# EFM32JG12B500F1024GL125 register map
File version: 4.0.0
CPU: CM3 r2p1, little endian, MPU, no FPU, 3 interrupt priority bits
Registers are 32-bit, read-write, reset 0x0 unless marked. A register's access mark holds for its fields unless they carry their own. Offsets are from the block's base; [hi:lo] are bit positions; {n}, {i} and the like mark numbered series.

## VDAC0
Base 0x40008000
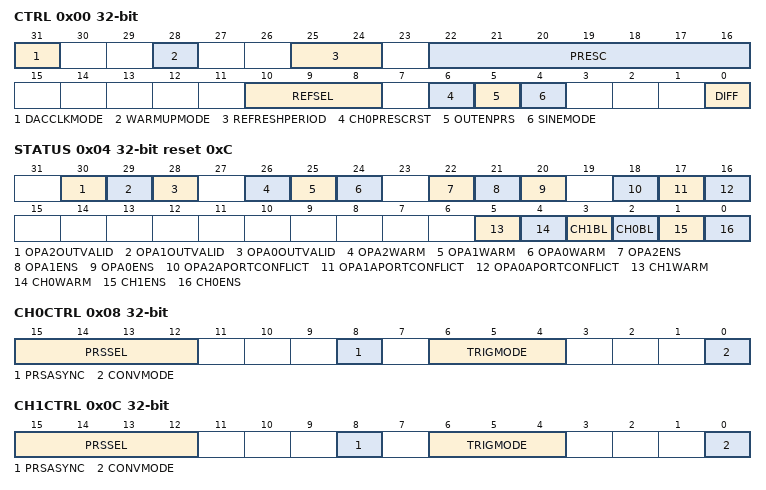
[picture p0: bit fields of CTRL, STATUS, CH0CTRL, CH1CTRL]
0x00 CTRL — Control Register
  [31] DACCLKMODE — Clock Mode
  [28] WARMUPMODE
  [25:24] REFRESHPERIOD
    0=8CYCLES (All channels with enabled refresh are refreshed every 8 DAC_CLK cycles); 1=16CYCLES (All channels with enabled refresh are refreshed every 16 DAC_CLK cycles); 2=32CYCLES (All channels with enabled refresh are refreshed every 32 DAC_CLK cycles); 3=64CYCLES (All channels with enabled refresh are refreshed every 64 DAC_CLK cycles)
  [22:16] PRESC — Prescaler Setting for DAC Clock
    0=NODIVISION
  [10:8] REFSEL — Reference Selection
    0=1V25LN (Internal low noise 1.25 V bandgap reference); 1=2V5LN (Internal low noise 2.5 V bandgap reference); 2=1V25 (Internal 1.25 V bandgap reference); 3=2V5 (Internal 2.5 V bandgap reference); 4=VDD (AVDD reference); 6=EXT (External pin reference)
  [6] CH0PRESCRST — Channel 0 Start Reset Prescaler
  [5] OUTENPRS — PRS Controlled Output Enable
  [4] SINEMODE
  [0] DIFF — Differential Mode
0x04 STATUS ro reset 0xC
  [30] OPA2OUTVALID — OPA2 Output Valid Status
  [29] OPA1OUTVALID — OPA1 Output Valid Status
  [28] OPA0OUTVALID — OPA0 Output Valid Status
  [26] OPA2WARM — OPA2 Warm Status
  [25] OPA1WARM — OPA1 Warm Status
  [24] OPA0WARM — OPA0 Warm Status
  [22] OPA2ENS — OPA2 Enabled Status
  [21] OPA1ENS — OPA1 Enabled Status
  [20] OPA0ENS — OPA0 Enabled Status
  [18] OPA2APORTCONFLICT — OPA2 Bus Conflict Output
  [17] OPA1APORTCONFLICT — OPA1 Bus Conflict Output
  [16] OPA0APORTCONFLICT — OPA0 Bus Conflict Output
  [5] CH1WARM — Channel 1 Warm
  [4] CH0WARM — Channel 0 Warm
  [3] CH1BL — Channel 1 Buffer Level
  [2] CH0BL — Channel 0 Buffer Level
  [1] CH1ENS — Channel 1 Enabled Status
  [0] CH0ENS — Channel 0 Enabled Status
0x08 CH0CTRL — Channel 0 Control Register
  [15:12] PRSSEL — Channel 0 PRS Trigger Select
    {v}=PRSCH{v} (PRS ch {v} triggers a conversion.) (v=0..11)
  [8] PRSASYNC — Channel 0 PRS Asynchronous Enable
  [6:4] TRIGMODE — Channel 0 Trigger Mode
    0=SW (Channel 0 is triggered by CH0DATA or COMBDATA write); 1=PRS (Channel 0 is triggered by PRS input); 2=REFRESH (Channel 0 is triggered by Refresh timer); 3=SWPRS (Channel 0 is triggered by CH0DATA/COMBDATA write or PRS input); 4=SWREFRESH (Channel 0 is triggered by CH0DATA/COMBDATA write or Refresh timer); 5=LESENSE (Channel 0 is triggered by LESENSE)
  [0] CONVMODE — Conversion Mode
0x0C CH1CTRL — Channel 1 Control Register
  [15:12] PRSSEL — Channel 1 PRS Trigger Select
    {v}=PRSCH{v} (PRS ch {v} triggers a conversion.) (v=0..11)
  [8] PRSASYNC — Channel 1 PRS Asynchronous Enable
  [6:4] TRIGMODE — Channel 1 Trigger Mode
    0=SW (Channel 1 is triggered by CH1DATA or COMBDATA write); 1=PRS (Channel 1 is triggered by PRS input); 2=REFRESH (Channel 1 is triggered by Refresh timer); 3=SWPRS (Channel 1 is triggered by CH1DATA/COMBDATA write or PRS input); 4=SWREFRESH (Channel 1 is triggered by CH1DATA/COMBDATA write or Refresh timer); 5=LESENSE (Channel 1 is triggered by LESENSE)
  [0] CONVMODE — Conversion Mode
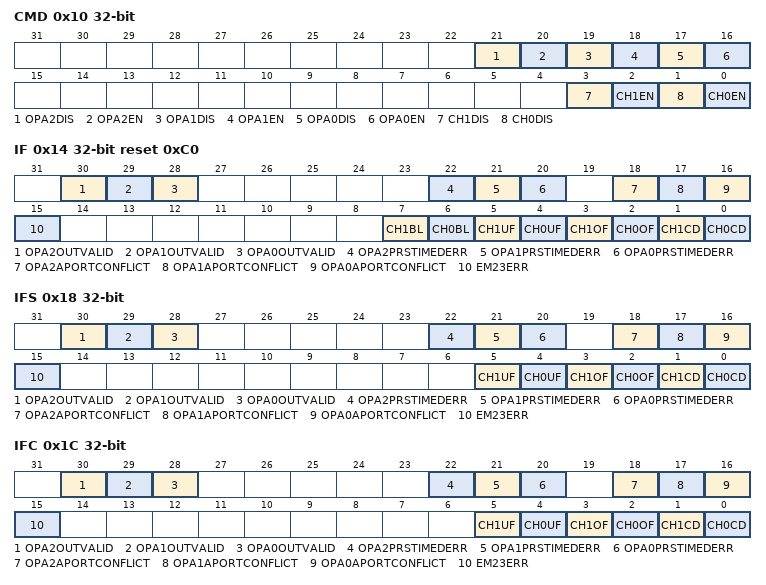
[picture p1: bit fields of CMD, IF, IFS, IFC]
0x10 CMD wo — Command Register
  [21] OPA2DIS — OPA2 Disable
  [20] OPA2EN — OPA2 Enable
  [19] OPA1DIS — OPA1 Disable
  [18] OPA1EN — OPA1 Enable
  [17] OPA0DIS — OPA0 Disable
  [16] OPA0EN — OPA0 Enable
  [3] CH1DIS — DAC Channel 1 Disable
  [2] CH1EN — DAC Channel 1 Enable
  [1] CH0DIS — DAC Channel 0 Disable
  [0] CH0EN — DAC Channel 0 Enable
0x14 IF ro reset 0xC0 — Interrupt Flag Register
  [30] OPA2OUTVALID — OPA3 Output Valid Interrupt Flag
  [29] OPA1OUTVALID — OPA1 Output Valid Interrupt Flag
  [28] OPA0OUTVALID — OPA0 Output Valid Interrupt Flag
  [22] OPA2PRSTIMEDERR — OPA2 PRS Trigger Mode Error Interrupt Flag
  [21] OPA1PRSTIMEDERR — OPA1 PRS Trigger Mode Error Interrupt Flag
  [20] OPA0PRSTIMEDERR — OPA0 PRS Trigger Mode Error Interrupt Flag
  [18] OPA2APORTCONFLICT — OPA2 Bus Conflict Output Interrupt Flag
  [17] OPA1APORTCONFLICT — OPA1 Bus Conflict Output Interrupt Flag
  [16] OPA0APORTCONFLICT — OPA0 Bus Conflict Output Interrupt Flag
  [15] EM23ERR — EM2/3 Entry Error Flag
  [7] CH1BL — Channel 1 Buffer Level Interrupt Flag
  [6] CH0BL — Channel 0 Buffer Level Interrupt Flag
  [5] CH1UF — Channel 1 Data Underflow Interrupt Flag
  [4] CH0UF — Channel 0 Data Underflow Interrupt Flag
  [3] CH1OF — Channel 1 Data Overflow Interrupt Flag
  [2] CH0OF — Channel 0 Data Overflow Interrupt Flag
  [1] CH1CD — Channel 1 Conversion Done Interrupt Flag
  [0] CH0CD — Channel 0 Conversion Done Interrupt Flag
0x18 IFS wo — Interrupt Flag Set Register
  [30] OPA2OUTVALID — Set OPA2OUTVALID Interrupt Flag
  [29] OPA1OUTVALID — Set OPA1OUTVALID Interrupt Flag
  [28] OPA0OUTVALID — Set OPA0OUTVALID Interrupt Flag
  [22] OPA2PRSTIMEDERR — Set OPA2PRSTIMEDERR Interrupt Flag
  [21] OPA1PRSTIMEDERR — Set OPA1PRSTIMEDERR Interrupt Flag
  [20] OPA0PRSTIMEDERR — Set OPA0PRSTIMEDERR Interrupt Flag
  [18] OPA2APORTCONFLICT — Set OPA2APORTCONFLICT Interrupt Flag
  [17] OPA1APORTCONFLICT — Set OPA1APORTCONFLICT Interrupt Flag
  [16] OPA0APORTCONFLICT — Set OPA0APORTCONFLICT Interrupt Flag
  [15] EM23ERR — Set EM23ERR Interrupt Flag
  [5] CH1UF — Set CH1UF Interrupt Flag
  [4] CH0UF — Set CH0UF Interrupt Flag
  [3] CH1OF — Set CH1OF Interrupt Flag
  [2] CH0OF — Set CH0OF Interrupt Flag
  [1] CH1CD — Set CH1CD Interrupt Flag
  [0] CH0CD — Set CH0CD Interrupt Flag
0x1C IFC wo — Interrupt Flag Clear Register
  [30] OPA2OUTVALID — Clear OPA2OUTVALID Interrupt Flag
  [29] OPA1OUTVALID — Clear OPA1OUTVALID Interrupt Flag
  [28] OPA0OUTVALID — Clear OPA0OUTVALID Interrupt Flag
  [22] OPA2PRSTIMEDERR — Clear OPA2PRSTIMEDERR Interrupt Flag
  [21] OPA1PRSTIMEDERR — Clear OPA1PRSTIMEDERR Interrupt Flag
  [20] OPA0PRSTIMEDERR — Clear OPA0PRSTIMEDERR Interrupt Flag
  [18] OPA2APORTCONFLICT — Clear OPA2APORTCONFLICT Interrupt Flag
  [17] OPA1APORTCONFLICT — Clear OPA1APORTCONFLICT Interrupt Flag
  [16] OPA0APORTCONFLICT — Clear OPA0APORTCONFLICT Interrupt Flag
  [15] EM23ERR — Clear EM23ERR Interrupt Flag
  [5] CH1UF — Clear CH1UF Interrupt Flag
  [4] CH0UF — Clear CH0UF Interrupt Flag
  [3] CH1OF — Clear CH1OF Interrupt Flag
  [2] CH0OF — Clear CH0OF Interrupt Flag
  [1] CH1CD — Clear CH1CD Interrupt Flag
  [0] CH0CD — Clear CH0CD Interrupt Flag
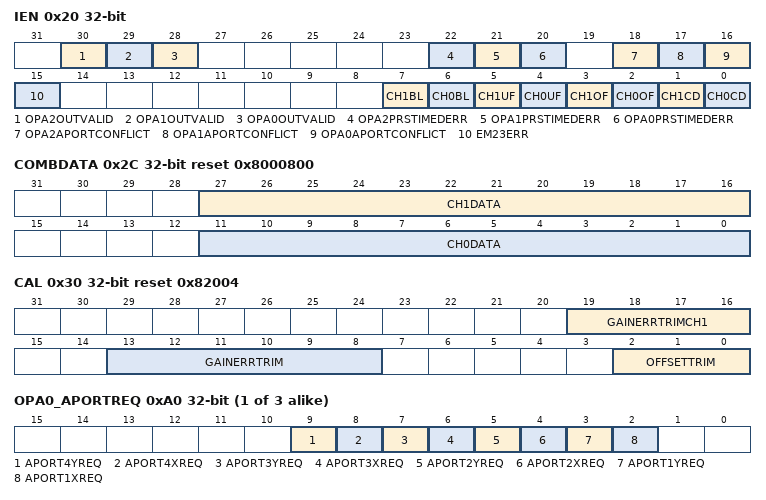
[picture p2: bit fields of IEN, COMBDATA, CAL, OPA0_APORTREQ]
0x20 IEN — Interrupt Enable Register
  [30] OPA2OUTVALID — OPA2OUTVALID Interrupt Enable
  [29] OPA1OUTVALID — OPA1OUTVALID Interrupt Enable
  [28] OPA0OUTVALID — OPA0OUTVALID Interrupt Enable
  [22] OPA2PRSTIMEDERR — OPA2PRSTIMEDERR Interrupt Enable
  [21] OPA1PRSTIMEDERR — OPA1PRSTIMEDERR Interrupt Enable
  [20] OPA0PRSTIMEDERR — OPA0PRSTIMEDERR Interrupt Enable
  [18] OPA2APORTCONFLICT — OPA2APORTCONFLICT Interrupt Enable
  [17] OPA1APORTCONFLICT — OPA1APORTCONFLICT Interrupt Enable
  [16] OPA0APORTCONFLICT — OPA0APORTCONFLICT Interrupt Enable
  [15] EM23ERR — EM23ERR Interrupt Enable
  [7] CH1BL — CH1BL Interrupt Enable
  [6] CH0BL — CH0BL Interrupt Enable
  [5] CH1UF — CH1UF Interrupt Enable
  [4] CH0UF — CH0UF Interrupt Enable
  [3] CH1OF — CH1OF Interrupt Enable
  [2] CH0OF — CH0OF Interrupt Enable
  [1] CH1CD — CH1CD Interrupt Enable
  [0] CH0CD — CH0CD Interrupt Enable
0x24 CH0DATA reset 0x800 — Channel 0 Data Register
  [11:0] DATA — Channel 0 Data
0x28 CH1DATA reset 0x800 — Channel 1 Data Register
  [11:0] DATA — Channel 1 Data
0x2C COMBDATA reset 0x8000800 — Combined Data Register
  [27:16] CH1DATA — Channel 1 Data
  [11:0] CH0DATA — Channel 0 Data
0x30 CAL reset 0x82004 — Calibration Register
  [19:16] GAINERRTRIMCH1 — Gain Error Trim Value for CH1
  [13:8] GAINERRTRIM — Gain Error Trim Value
  [2:0] OFFSETTRIM — Input Buffer Offset Calibration Value
{0xA0+0x20*i} OPA{i}_APORTREQ ro (i=0..2) — Operational Amplifier APORT Request Status Register
  [9] APORT4YREQ — 1 If the Bus Connected to APORT4Y is Requested
  [8] APORT4XREQ — 1 If the Bus Connected to APORT4X is Requested
  [7] APORT3YREQ — 1 If the Bus Connected to APORT3Y is Requested
  [6] APORT3XREQ — 1 If the Bus Connected to APORT3X is Requested
  [5] APORT2YREQ — 1 If the Bus Connected to APORT2Y is Requested
  [4] APORT2XREQ — 1 If the Bus Connected to APORT2X is Requested
  [3] APORT1YREQ — 1 If the Bus Connected to APORT1X is Requested
  [2] APORT1XREQ — 1 If the Bus Connected to APORT2X is Requested
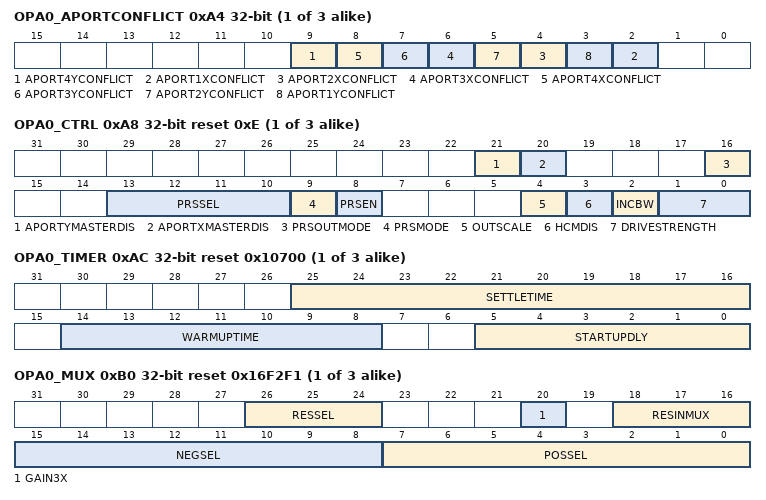
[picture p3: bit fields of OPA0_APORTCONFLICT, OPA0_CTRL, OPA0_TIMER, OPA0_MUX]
{0xA4+0x20*i} OPA{i}_APORTCONFLICT ro (i=0..2) — Operational Amplifier APORT Conflict Status Register
  [9] APORT4YCONFLICT — 1 If the Bus Connected to APORT4Y is in Conflict With Another Peripheral
  [2n] APORT{n}XCONFLICT (n=1..4) — 1 If the Bus Connected to APORT{n}X is in Conflict With Another Peripheral
  [7] APORT3YCONFLICT — 1 If the Bus Connected to APORT3Y is in Conflict With Another Peripheral
  [5] APORT2YCONFLICT — 1 If the Bus Connected to APORT2Y is in Conflict With Another Peripheral
  [3] APORT1YCONFLICT — 1 If the Bus Connected to APORT1X is in Conflict With Another Peripheral
{0xA8+0x20*i} OPA{i}_CTRL reset 0xE (i=0..2) — Operational Amplifier Control Register
  [21] APORTYMASTERDIS — APORT Bus Master Disable
  [20] APORTXMASTERDIS — APORT Bus Master Disable
  [16] PRSOUTMODE — OPAx PRS Output Select
  [13:10] PRSSEL — OPAx PRS Trigger Select
    {v}=PRSCH{v} (PRS ch {v} triggers OPA.) (v=0..11)
  [9] PRSMODE — OPAx PRS Trigger Mode
  [8] PRSEN — OPAx PRS Trigger Enable
  [4] OUTSCALE — Scale OPAx Output Driving Strength
  [3] HCMDIS — High Common Mode Disable
  [2] INCBW — OPAx Unity Gain Bandwidth Scale
  [1:0] DRIVESTRENGTH — OPAx Operation Mode
    0=Lower accuracy with Low drive strength; 1=Low accuracy with Low drive strength; 2=High accuracy with High drive strength; 3=Higher accuracy with High drive strength
{0xAC+0x20*i} OPA{i}_TIMER reset 0x10700 (i=0..2) — Operational Amplifier Timer Control Register
  [25:16] SETTLETIME — OPAx Output Settling Timeout Value
  [14:8] WARMUPTIME — OPAx Warmup Time Count Value
  [5:0] STARTUPDLY — OPAx Startup Delay Count Value
{0xB0+0x20*i} OPA{i}_MUX reset 0x16F2F1 (i=0..2) — Operational Amplifier Mux Configuration Register
  [26:24] RESSEL — OPAx Resistor Ladder Select
    0=RES0 (Gain of 1/3); 1=RES1 (Gain of 1); 2=RES2 (Gain of 1 2/3); 3=RES3 (Gain of 2 1/5); 4=RES4 (Gain of 3); 5=RES5 (Gain of 4 1/3); 6=RES6 (Gain of 7); 7=RES7 (Gain of 15)
  [20] GAIN3X — OPAx Dedicated 3x Gain Resistor Ladder
  [18:16] RESINMUX — OPAx Resistor Ladder Input Mux
    0=DISABLE (Set for Unity Gain); 1=OPANEXT (Set for NEXTOUT(x-1) input); 2=NEGPAD (NEG pad connected); 3=POSPAD (POS pad connected); 4=COMPAD (Neg pad of OPA0 connected. Direct input to support common reference.); 5=CENTER (OPA0 and OPA1 Resmux connected to form fully differential instrumentation amplifier.); 6=VSS (VSS connected)
  [15:8] NEGSEL — OPAx Inverting Input Mux
  [7:0] POSSEL — OPAx Non-inverting Input Mux
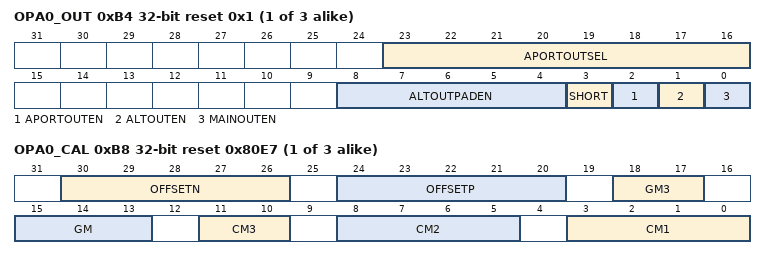
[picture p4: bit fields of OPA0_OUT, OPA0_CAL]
{0xB4+0x20*i} OPA{i}_OUT reset 0x1 (i=0..2) — Operational Amplifier Output Configuration Register
  [23:16] APORTOUTSEL — OPAx APORT Output
  [8:4] ALTOUTPADEN — OPAx Output Enable Value
    1=OUT0 (Alternate Output 0); 2=OUT1 (Alternate Output 1); 4=OUT2 (Alternate Output 2); 8=OUT3 (Alternate Output 3); 16=OUT4 (Alternate Output 4)
  [3] SHORT — OPAx Main and Alternative Output Short
  [2] APORTOUTEN — OPAx Aport Output Enable
  [1] ALTOUTEN — OPAx Alternative Output Enable
  [0] MAINOUTEN — OPAx Main Output Enable
{0xB8+0x20*i} OPA{i}_CAL reset 0x80E7 (i=0..2) — Operational Amplifier Calibration Register
  [30:26] OFFSETN — OPAx Inverting Input Offset Configuration Value
  [24:20] OFFSETP — OPAx Non-Inverting Input Offset Configuration Value
  [18:17] GM3 — Gm3 Trim Value
  [15:13] GM — Gm Trim Value
  [11:10] CM3 — Compensation Cap Cm3 Trim Value
  [8:5] CM2 — Compensation Cap Cm2 Trim Value
  [3:0] CM1 — Compensation Cap Cm1 Trim Value
